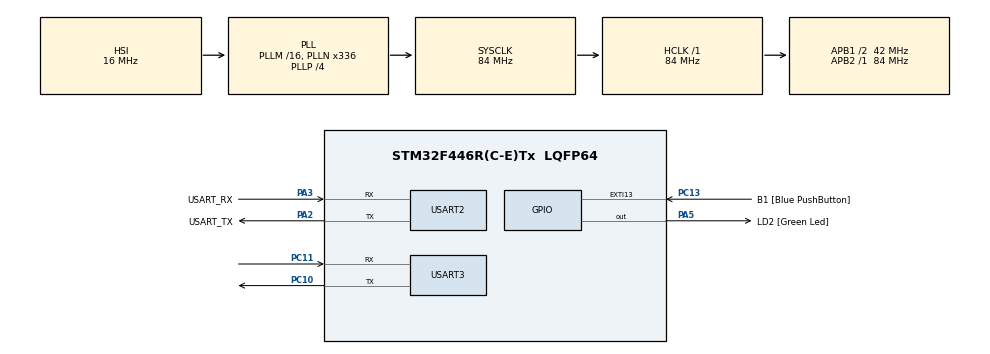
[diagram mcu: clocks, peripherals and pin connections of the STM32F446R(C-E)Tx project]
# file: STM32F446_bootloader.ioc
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Mcu.Family=STM32F4
Mcu.Name=STM32F446R(C-E)Tx
Mcu.Package=LQFP64
NVIC.PriorityGroup=NVIC_PRIORITYGROUP_0
PA13.GPIO_Label=TMS
PA13.Mode=Serial_Wire
PA13.Signal=SYS_JTMS-SWDIO
PA14.GPIO_Label=TCK
PA14.Mode=Serial_Wire
PA14.Signal=SYS_JTCK-SWCLK
PA2.GPIO_Label=USART_TX
PA2.Mode=Asynchronous
PA2.Signal=USART2_TX
PA3.GPIO_Label=USART_RX
PA3.Mode=Asynchronous
PA3.Signal=USART2_RX
PA5.GPIO_Label=LD2 [Green Led]
PA5.Signal=GPIO_Output
PB3.GPIO_Label=SWO
PB3.Signal=SYS_JTDO-SWO
PC10.Mode=Asynchronous
PC10.Signal=USART3_TX
PC11.Mode=Asynchronous
PC11.Signal=USART3_RX
PC13.GPIO_Label=B1 [Blue PushButton]
PC13.GPIO_ModeDefaultEXTI=GPIO_MODE_IT_FALLING
PC13.Signal=GPXTI13
PC14-OSC32_IN.Mode=LSE-External-Oscillator
PC14-OSC32_IN.Signal=RCC_OSC32_IN
PC15-OSC32_OUT.Mode=LSE-External-Oscillator
PC15-OSC32_OUT.Signal=RCC_OSC32_OUT
PH0-OSC_IN.Mode=HSE-External-Oscillator
PH0-OSC_IN.Signal=RCC_OSC_IN
PH1-OSC_OUT.Mode=HSE-External-Oscillator
PH1-OSC_OUT.Signal=RCC_OSC_OUT
ProjectManager.HeapSize=0x200
ProjectManager.StackSize=0x400
ProjectManager.TargetToolchain=STM32CubeIDE
RCC.48MHZClocksFreq_Value=84000000
RCC.AHBFreq_Value=84000000
RCC.APB1CLKDivider=RCC_HCLK_DIV2
RCC.APB1Freq_Value=42000000
RCC.APB1TimFreq_Value=84000000
RCC.APB2Freq_Value=84000000
RCC.APB2TimFreq_Value=84000000
RCC.CortexFreq_Value=84000000
RCC.FLatency-AdvancedSettings=FLASH_LATENCY_2
RCC.HCLKFreq_Value=84000000
RCC.HSE_VALUE=8000000
RCC.HSI_VALUE=16000000
RCC.PLLN=336
RCC.PLLP=RCC_PLLP_DIV4
RCC.SYSCLKFreq_VALUE=84000000
RCC.SYSCLKSource=RCC_SYSCLKSOURCE_PLLCLK
RCC.USBFreq_Value=168000000
RCC.VCOOutputFreq_Value=336000000
USART2.VirtualMode=VM_ASYNC
USART3.VirtualMode=VM_ASYNC
VP_CRC_VS_CRC.Mode=CRC_Activate
board=NUCLEO-F446RE

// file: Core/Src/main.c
/* USER CODE BEGIN Header */
/**
  ******************************************************************************
  * @file           : main.c
  * @brief          : Main program body
  ******************************************************************************
  * @attention
  *
  * Copyright (c) 2025 STMicroelectronics.
  * All rights reserved.
  *
  * This software is licensed under terms that can be found in the LICENSE file
  * in the root directory of this software component.
  * If no LICENSE file comes with this software, it is provided AS-IS.
  *
  ******************************************************************************
  */
/* USER CODE END Header */
#include "main.h"
#include "stm32f4xx_hal.h"  // Change to your STM32 series header
#include <stdarg.h>
#include <stdio.h>
#include <string.h>
#include <stdint.h>

CRC_HandleTypeDef hcrc;

UART_HandleTypeDef huart2;
UART_HandleTypeDef huart3;
#define Command_UART	&huart2
#define Data_UART 		&huart3

void SystemClock_Config(void);
static void MX_GPIO_Init(void);
static void MX_USART2_UART_Init(void);
static void MX_CRC_Init(void);
static void MX_USART3_UART_Init(void);

/* USER CODE BEGIN 0 */
uint8_t BL_rx_buff[BL_RX_SIZE];
/* USER CODE END 0 */

int main(void)
{

  /* MCU Configuration--------------------------------------------------------*/

  /* Reset of all peripherals, Initializes the Flash interface and the Systick. */
  HAL_Init();

  /* Configure the system clock */
  SystemClock_Config();

  /* Initialize all configured peripherals */
  MX_GPIO_Init();
  MX_USART2_UART_Init();
  MX_CRC_Init();
  MX_USART3_UART_Init();

  /* USER CODE BEGIN WHILE */
 if(HAL_GPIO_ReadPin(B1_GPIO_Port, B1_Pin)==GPIO_PIN_RESET){
	 uart_printf("Reset button pressed...Transition to BL mode\n\r");
	 BL_UART_read_data();
 }
 else{
	 uart_printf("Executing user app\n\r");
	 userApp();
 }

 /* Infinite loop */
 /* USER CODE BEGIN WHILE */
 while (1)
 {
   /* USER CODE END WHILE */

 }
}

void BL_UART_read_data(void)
{
	uint8_t packet_len = 0;
	while (1)
	{
		memset(BL_rx_buff, 0 , 200); //initialize with 0s

		// read and decode the commands coming from host
		HAL_UART_Receive(Command_UART, BL_rx_buff, 1, HAL_MAX_DELAY); //read one byte from the host, which is the length field of the command packet
		packet_len = BL_rx_buff[0];
		HAL_UART_Receive(Command_UART, &BL_rx_buff[1], packet_len, HAL_MAX_DELAY);

		switch (BL_rx_buff[1])
		{
			case BL_GET_VER:
				BL_getver_handler(BL_rx_buff);
				break;
			case BL_GET_RDP_STATUS:
				BL_getrdp_handler(BL_rx_buff);
			case BL_FLASH_ERASE:
				BL_flash_erase_handler(BL_rx_buff);
			default:
				uart_printf("Invalid command received from host\r\n");
		}

	}
}

void userApp(void){
	uart_printf("Running userApp func\n\r");

	// function pointer to hold the address of the reset handler of the user application
	void (*app_reset_handler)(void);

	// configure the MSP by reading the value from the base address of the sector 2
	uint32_t MSP = *(volatile uint32_t *) FLASH_SECTOR2_BASE_ADDRESS;
	uart_printf("MSP value: %#x\n\r", MSP);

	//set the MSP value
	__set_MSP(MSP);

	//fetch the reset handler address of the user application
	uint32_t resethandler_address  = *(volatile uint32_t * ) (FLASH_SECTOR2_BASE_ADDRESS + 4);

	// jump to reset handler of user application
	app_reset_handler = (void *) resethandler_address;
	uart_printf("Application reset handler addr: %#x\n\r", app_reset_handler);

	app_reset_handler();
}

void uart_printf (const char *fmt, ...) {
    char buffer[128];  // Adjust size as needed
    va_list args;
    va_start(args, fmt);
    vsnprintf(buffer, sizeof(buffer), fmt, args);
    va_end(args);
    HAL_UART_Transmit(&huart2, (uint8_t *)buffer, strlen(buffer), HAL_MAX_DELAY);
}

/*Bootloader handler function implementations*/
void BL_getver_handler(uint8_t *rx_buffer)
{
	//uart_printf("we are in getver command execution\r\n");
	uint32_t cmd_packet_len = rx_buffer[0] + 1;
	uint8_t BL_version;
	// extract CRC sent by host
	uint32_t host_crc = *((uint32_t *)(rx_buffer + cmd_packet_len - 4));

	if (!BL_CRC_check(&rx_buffer[0], cmd_packet_len-4, host_crc)){
		//uart_printf("Check sum success\r\n");
		BL_version = (uint8_t)BL_VERSION;
		BL_send_ack(rx_buffer[0], 1);
		uart_printf("Bootloader version: %d %#x\r\n",BL_version,BL_version );
		HAL_UART_Transmit(Command_UART,(uint8_t*)BL_version,1,HAL_MAX_DELAY);

	}else{
		uart_printf("Check sum failed\r\n");
		BL_send_nack();
	}
}

void BL_getrdp_handler(uint8_t *rx_buffer)
{
	uint8_t rdp_val = 0x00;
	volatile uint32_t *pOptionByte = (uint32_t*)0x1FFFC000;
	rdp_val = (uint8_t)(*pOptionByte >> 8); //reads bits 8 to 15 for protection level: 0xAA (L0), 0xCC(L2), and other(L1) for different protection levels
	uint32_t cmd_packet_len = rx_buffer[0] + 1;
	uint32_t host_crc = *((uint32_t *)(rx_buffer + cmd_packet_len - 4));

	if (!BL_CRC_check(&rx_buffer[0], cmd_packet_len-4, host_crc)){
		BL_send_ack(rx_buffer[0], 1);
		uart_printf("RDP level: %d %#x\n",rdp_val,rdp_val );
		HAL_UART_Transmit(Command_UART,rdp_val,sizeof(rdp_val),HAL_MAX_DELAY);

	}else{
		uart_printf("BL_DEBUG_MSG:checksum fail !!\n");
		BL_send_nack();
	}

}

void BL_flash_erase_handler(uint8_t *rx_buffer)
{
	uint8_t erase_status = 0x00;
	uint32_t cmd_packet_len = rx_buffer[0] + 1;
	uint32_t host_crc = *((uint32_t *)(rx_buffer + cmd_packet_len - 4));

	if (!BL_CRC_check(&rx_buffer[0], cmd_packet_len-4, host_crc)){
		BL_send_ack(rx_buffer[0], 1);

		HAL_GPIO_WritePin(LD2_GPIO_Port, LD2_Pin, 1);
		erase_status = flash_erase(rx_buffer[2], rx_buffer[3]);
		HAL_GPIO_WritePin(LD2_GPIO_Port, LD2_Pin, 0);

		HAL_UART_Transmit(Command_UART,&erase_status,sizeof(erase_status),HAL_MAX_DELAY);

	}else{
		uart_printf("BL_DEBUG_MSG:checksum fail !!\n");
		BL_send_nack();
	}

}

void SystemClock_Config(void)
{
  RCC_OscInitTypeDef RCC_OscInitStruct = {0};
  RCC_ClkInitTypeDef RCC_ClkInitStruct = {0};

  /** Configure the main internal regulator output voltage
  */
  __HAL_RCC_PWR_CLK_ENABLE();
  __HAL_PWR_VOLTAGESCALING_CONFIG(PWR_REGULATOR_VOLTAGE_SCALE3);

  /** Initializes the RCC Oscillators according to the specified parameters
  * in the RCC_OscInitTypeDef structure.
  */
  RCC_OscInitStruct.OscillatorType = RCC_OSCILLATORTYPE_HSI;
  RCC_OscInitStruct.HSIState = RCC_HSI_ON;
  RCC_OscInitStruct.HSICalibrationValue = RCC_HSICALIBRATION_DEFAULT;
  RCC_OscInitStruct.PLL.PLLState = RCC_PLL_ON;
  RCC_OscInitStruct.PLL.PLLSource = RCC_PLLSOURCE_HSI;
  RCC_OscInitStruct.PLL.PLLM = 16;
  RCC_OscInitStruct.PLL.PLLN = 336;
  RCC_OscInitStruct.PLL.PLLP = RCC_PLLP_DIV4;
  RCC_OscInitStruct.PLL.PLLQ = 2;
  RCC_OscInitStruct.PLL.PLLR = 2;
  if (HAL_RCC_OscConfig(&RCC_OscInitStruct) != HAL_OK)
  {
    Error_Handler();
  }

  /** Initializes the CPU, AHB and APB buses clocks
  */
  RCC_ClkInitStruct.ClockType = RCC_CLOCKTYPE_HCLK|RCC_CLOCKTYPE_SYSCLK
                              |RCC_CLOCKTYPE_PCLK1|RCC_CLOCKTYPE_PCLK2;
  RCC_ClkInitStruct.SYSCLKSource = RCC_SYSCLKSOURCE_PLLCLK;
  RCC_ClkInitStruct.AHBCLKDivider = RCC_SYSCLK_DIV1;
  RCC_ClkInitStruct.APB1CLKDivider = RCC_HCLK_DIV2;
  RCC_ClkInitStruct.APB2CLKDivider = RCC_HCLK_DIV1;

  if (HAL_RCC_ClockConfig(&RCC_ClkInitStruct, FLASH_LATENCY_2) != HAL_OK)
  {
    Error_Handler();
  }
}

static void MX_CRC_Init(void)
{

  hcrc.Instance = CRC;
  if (HAL_CRC_Init(&hcrc) != HAL_OK)
  {
    Error_Handler();
  }

}

static void MX_USART2_UART_Init(void)
{

  huart2.Instance = USART2;
  huart2.Init.BaudRate = 115200;
  huart2.Init.WordLength = UART_WORDLENGTH_8B;
  huart2.Init.StopBits = UART_STOPBITS_1;
  huart2.Init.Parity = UART_PARITY_NONE;
  huart2.Init.Mode = UART_MODE_TX_RX;
  huart2.Init.HwFlowCtl = UART_HWCONTROL_NONE;
  huart2.Init.OverSampling = UART_OVERSAMPLING_16;
  if (HAL_UART_Init(&huart2) != HAL_OK)
  {
    Error_Handler();
  }

}

static void MX_USART3_UART_Init(void)
{

  huart3.Instance = USART3;
  huart3.Init.BaudRate = 115200;
  huart3.Init.WordLength = UART_WORDLENGTH_8B;
  huart3.Init.StopBits = UART_STOPBITS_1;
  huart3.Init.Parity = UART_PARITY_NONE;
  huart3.Init.Mode = UART_MODE_TX_RX;
  huart3.Init.HwFlowCtl = UART_HWCONTROL_NONE;
  huart3.Init.OverSampling = UART_OVERSAMPLING_16;
  if (HAL_UART_Init(&huart3) != HAL_OK)
  {
    Error_Handler();
  }

}

static void MX_GPIO_Init(void)
{
  GPIO_InitTypeDef GPIO_InitStruct = {0};

  /* GPIO Ports Clock Enable */
  __HAL_RCC_GPIOC_CLK_ENABLE();
  __HAL_RCC_GPIOH_CLK_ENABLE();
  __HAL_RCC_GPIOA_CLK_ENABLE();
  __HAL_RCC_GPIOB_CLK_ENABLE();

  /*Configure GPIO pin Output Level */
  HAL_GPIO_WritePin(LD2_GPIO_Port, LD2_Pin, GPIO_PIN_RESET);

  /*Configure GPIO pin : B1_Pin */
  GPIO_InitStruct.Pin = B1_Pin;
  GPIO_InitStruct.Mode = GPIO_MODE_IT_FALLING;
  GPIO_InitStruct.Pull = GPIO_NOPULL;
  HAL_GPIO_Init(B1_GPIO_Port, &GPIO_InitStruct);

  /*Configure GPIO pin : LD2_Pin */
  GPIO_InitStruct.Pin = LD2_Pin;
  GPIO_InitStruct.Mode = GPIO_MODE_OUTPUT_PP;
  GPIO_InitStruct.Pull = GPIO_NOPULL;
  GPIO_InitStruct.Speed = GPIO_SPEED_FREQ_LOW;
  HAL_GPIO_Init(LD2_GPIO_Port, &GPIO_InitStruct);

}
void BL_send_ack(uint8_t command_code, uint8_t len){
	//send 2 bytes. first byte is ack and second len value
	uint8_t buffer[2];
	buffer[0] = BL_ACK;
	buffer[1] = len;
	HAL_UART_Transmit(Command_UART, buffer, 2, HAL_MAX_DELAY);
}

void BL_send_nack(void){
	uint8_t nack=BL_NACK;
	HAL_UART_Transmit(Command_UART, &nack, 1, HAL_MAX_DELAY);
}

uint8_t BL_CRC_check(uint8_t *pData, uint32_t len, uint32_t crc_host)
{
	uint32_t uwCRCValue = 0xff;
	for (uint32_t i = 0; i<len; i++){
		uint32_t i_data = pData[i];
		uwCRCValue = HAL_CRC_Accumulate(&hcrc, &i_data, 1);
	}
	//reset CRC
	__HAL_CRC_DR_RESET(&hcrc);
	if(uwCRCValue == crc_host){
		return VERIFY_CRC_SUCCESS;
	}
	return VERIFY_CRC_FAIL;
}

uint8_t flash_erase(uint8_t sector_num, uint8_t num_of_sectors){
	// number of sector between 0 and 7
	// if sector number = 0xff is used for mass errasin
	FLASH_EraseInitTypeDef FE_handle;
	uint32_t sectorError;
	HAL_StatusTypeDef status;

	if (sector_num == 0xff){
		FE_handle.TypeErase = FLASH_TYPEERASE_MASSERASE;
	}
	else{
		if (sector_num <= 7){
			FE_handle.TypeErase = FLASH_TYPEERASE_SECTORS;
			FE_handle.Sector = sector_num;
			FE_handle.NbSectors = num_of_sectors;
		}
	}
	FE_handle.Banks = FLASH_BANK_1;

	HAL_FLASH_Unlock();
	FE_handle.VoltageRange = FLASH_VOLTAGE_RANGE_3; //voltage range for this MCU
	status = (uint8_t)HAL_FLASHEx_Erase(&FE_handle, &sectorError);
	HAL_FLASH_Lock();

	return status;
}

void Error_Handler(void)
{
  __disable_irq();
  while (1)
  {
  }
}
